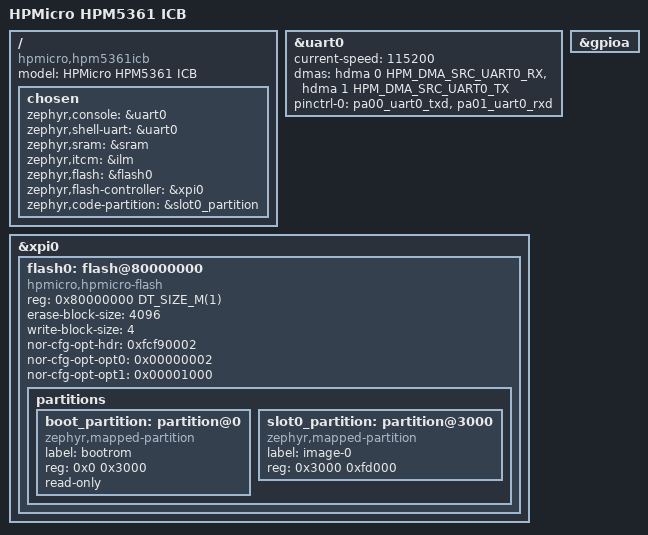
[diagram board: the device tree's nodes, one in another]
/*
 * Copyright (c) 2026 The HPM Zephyr Module Contributors
 * SPDX-License-Identifier: Apache-2.0
 */

/dts-v1/;

#include <dt-bindings/dma/hpmicro-hpm5300-dma.h>
#include <hpmicro/hpm5361.dtsi>
#include "hpm5361icb-pinctrl.dtsi"

/ {
	model = "HPMicro HPM5361 ICB";
	compatible = "hpmicro,hpm5361icb";

	chosen {
		zephyr,console = &uart0;
		zephyr,shell-uart = &uart0;
		zephyr,sram = &sram;
		zephyr,itcm = &ilm;
		zephyr,flash = &flash0;
		zephyr,flash-controller = &xpi0;
		zephyr,code-partition = &slot0_partition;
	};
};

&uart0 {
	status = "okay";
	current-speed = <115200>;
	dmas = <&hdma 0 HPM_DMA_SRC_UART0_RX>, <&hdma 1 HPM_DMA_SRC_UART0_TX>;
	dma-names = "rx", "tx";
	pinctrl-0 = <&pa00_uart0_txd &pa01_uart0_rxd>;
	pinctrl-names = "default";
};

&gpioa {
	status = "okay";
};

&xpi0 {
	status = "okay";

	flash0: flash@80000000 {
		compatible = "hpmicro,hpmicro-flash", "soc-nv-flash";
		reg = <0x80000000 DT_SIZE_M(1)>;
		ranges = <0x0 0x80000000 DT_SIZE_M(1)>;
		#address-cells = <1>;
		#size-cells = <1>;
		status = "okay";
		erase-block-size = <4096>;
		write-block-size = <4>;
		nor-cfg-opt-hdr = <0xfcf90002>;
		nor-cfg-opt-opt0 = <0x00000002>;
		nor-cfg-opt-opt1 = <0x00001000>;

		partitions {
			ranges;
			#address-cells = <1>;
			#size-cells = <1>;

			boot_partition: partition@0 {
				compatible = "zephyr,mapped-partition";
				label = "bootrom";
				reg = <0x0 0x3000>;
				read-only;
			};

			slot0_partition: partition@3000 {
				compatible = "zephyr,mapped-partition";
				label = "image-0";
				reg = <0x3000 0xfd000>;
			};
		};
	};
};
